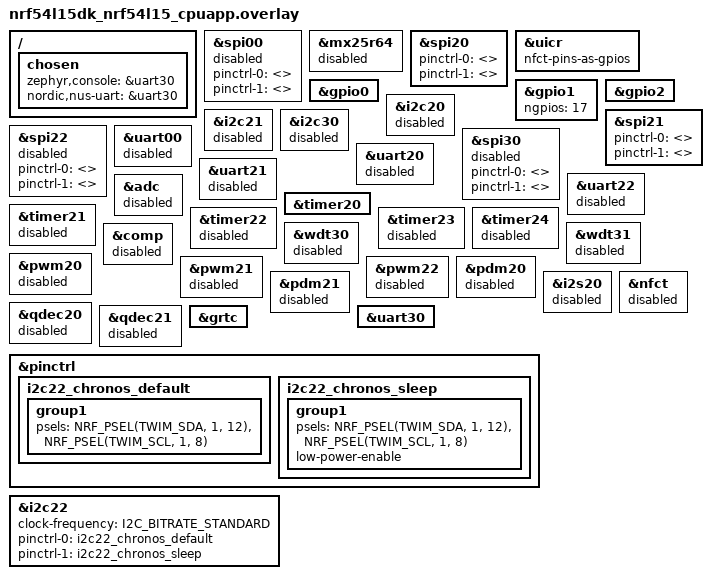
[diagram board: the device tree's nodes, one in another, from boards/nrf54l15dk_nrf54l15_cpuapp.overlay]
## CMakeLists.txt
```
cmake_minimum_required(VERSION 3.20.0)
find_package(Zephyr REQUIRED HINTS $ENV{ZEPHYR_BASE})

project(Chronos_nRF54_2)

target_sources(app PRIVATE
  src/main.c
  src/BLE.c
  src/data.c
  src/rtc_stim.c
  src/spi.c
  src/stim_nvm.c
  src/timer.c
)

if(CONFIG_BT)
  target_sources(app PRIVATE src/ble_session.c)
endif()

if(CONFIG_CHRONOS_ZMEAS)
  target_sources(app PRIVATE
    src/zmeas_gpio.c
    src/ad5933.c
  )
endif()
```

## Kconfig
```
mainmenu "Chronos"

source "Kconfig.zephyr"

config CHRONOS_ZMEAS
	bool "AD5933 impedance path (Phase A: I2C probe, P0.05 switch GPIO)"
	default y
	depends on I2C
	help
	  Enables I2C22 on P1.08 (SCL) / P1.12 (SDA), P0.05 electrode-route
	  switch GPIO, and boot-time AD5933 register readback.

config CHRONOS_ZMEAS_SWITCH_ACTIVE_HIGH
	bool "Impedance route switch: connect when P0.05 is high"
	default y
	depends on CHRONOS_ZMEAS

config CHRONOS_STIM_NVM
	bool "Persist stimulation settings in NVM (Settings/NVS + boot resume)"
	default y
	depends on BT
	help
	  Stores stim parameters and enabled flag in flash with CRC32.
	  When disabled, RAM defaults from config.h apply every boot and
	  boot-time stimulation resume is off (useful for power debugging).

	  When enabled, also set in prj.conf (Settings backend is a Kconfig
	  choice — cannot be auto-selected from here):
	    CONFIG_FLASH_MAP=y
	    CONFIG_FLASH_PAGE_LAYOUT=y
	    CONFIG_NVS=y
	    CONFIG_SETTINGS=y
	    CONFIG_SETTINGS_NVS=y
```

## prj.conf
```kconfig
##############################################################################
# BLE ON/OFF — set to n for RTC-only low-power stim (no radio)
##############################################################################
CONFIG_BT=y
CONFIG_BT_PERIPHERAL=y
CONFIG_BT_DEVICE_NAME="Chronos"
CONFIG_BT_MAX_CONN=1
CONFIG_BT_NUS=y
#CONFIG_BT_NUS_SECURITY_ENABLED=n

##############################################################################
# Peripherals: GPIO, SPIM1, TIMER0 (burst), TIMER2 (period)
##############################################################################
#CONFIG_NRFX=y
CONFIG_DEVICE_DT_METADATA=n
CONFIG_DEVICE_DEPS=n
CONFIG_NRFX_SPIM=y
CONFIG_NRFX_TIMER=y
CONFIG_GPIO=y

##############################################################################
# AD5933 / impedance (Phase A: I2C22 + P0.05 switch GPIO)
##############################################################################
CONFIG_CHRONOS_ZMEAS=y
CONFIG_CHRONOS_ZMEAS_SWITCH_ACTIVE_HIGH=y
CONFIG_I2C=y
#CONFIG_SPI=y
#CONFIG_NRFX_SPIM00=y
CONFIG_NRFX_QSPI=n
# TIMER: nRF54L15 uses TIMER20, TIMER22 etc. (enable per-instance in overlay if needed)
#CONFIG_NRFX_TIMER0=y
#CONFIG_NRFX_TIMER1=y

##############################################################################
# DK LEDs — off on custom (P1.10 = SPI MOSI; no DK LED routing)
##############################################################################
CONFIG_DK_LIBRARY=n

##############################################################################
# Heap / stacks (BLE needs more than RTC-only)
##############################################################################
CONFIG_HEAP_MEM_POOL_SIZE=8192
CONFIG_SYSTEM_WORKQUEUE_STACK_SIZE=2048
CONFIG_MAIN_STACK_SIZE=2048
CONFIG_BT_RX_STACK_SIZE=2048

##############################################################################
# UART / serial (NUS bridge on uart00; console is RTT, not UART)
# NUS sample path expects async UART; enables CONFIG_BT_NUS_UART_* sizes in Kconfig.
##############################################################################
CONFIG_SERIAL=y
CONFIG_UART_ASYNC_API=y

##############################################################################
# Console / log / debug (RTT via J-Link SWD — no UART console on custom board)
##############################################################################
CONFIG_CONSOLE=y
CONFIG_UART_CONSOLE=n
CONFIG_USE_SEGGER_RTT=y
CONFIG_RTT_CONSOLE=y
CONFIG_PRINTK=y
CONFIG_LOG=y
CONFIG_LOG_BACKEND_RTT=y
CONFIG_LOG_DEFAULT_LEVEL=2
CONFIG_DEBUG_THREAD_INFO=n
CONFIG_ASSERT=n

##############################################################################
# Boot / size
##############################################################################
CONFIG_BOOT_BANNER=n
CONFIG_NCS_BOOT_BANNER=n
CONFIG_SIZE_OPTIMIZATIONS=y

##############################################################################
# Stim NVM — set n to disable flash persistence and boot-time stim resume
# (useful for idle-current debug).
##############################################################################
CONFIG_CHRONOS_STIM_NVM=n

##############################################################################
# Flash. When CONFIG_CHRONOS_STIM_NVM=y, also uncomment the block below.
##############################################################################
CONFIG_FLASH=y
CONFIG_SPI_NOR=n
# CONFIG_FLASH_MAP=y
# CONFIG_FLASH_PAGE_LAYOUT=y
# CONFIG_NVS=y
# CONFIG_SETTINGS=y
# CONFIG_SETTINGS_NVS=y
```

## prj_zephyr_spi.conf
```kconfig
# Zephyr SPI test: use Zephyr SPI driver on spi20 instead of nrfx.
# Build with this as base conf (and zephyr_spi overlay) so CONFIG_SPI=y is set.
# Code uses #if defined(CONFIG_SPI) to run Zephyr SPI path; otherwise nrfx path.

CONFIG_SPI=y
```

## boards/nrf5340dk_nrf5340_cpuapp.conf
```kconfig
#
# Copyright (c) 2025 Nordic Semiconductor
#
# SPDX-License-Identifier: LicenseRef-Nordic-5-Clause
#

# Don't get entropy from HCI on nRF5340 devices
CONFIG_BT_HOST_CRYPTO_PRNG=y
CONFIG_ENTROPY_BT_HCI=n

# Power: use software crypto (Oberon) only; do not enable CryptoCell hardware
CONFIG_PSA_CRYPTO_DRIVER_CC3XX=n
CONFIG_PSA_CRYPTO_DRIVER_OBERON=y

# LFXO/32k RC: reverted - was increasing power on this design. Leave default (LFXO if enabled by board).
# CONFIG_CLOCK_CONTROL_NRF_K32SRC_RC=y
```

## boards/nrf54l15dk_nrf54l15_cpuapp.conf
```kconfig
#
# Copyright (c) 2024 Nordic Semiconductor
#
# SPDX-License-Identifier: LicenseRef-Nordic-5-Clause
#

# Disable the unspupported UART0 driver
CONFIG_NRFX_UARTE0=n

# nRF54L: SPIM00 (spi00) on P2.x; CS P2.05/P2.10 via direct P2 registers.
CONFIG_GPIO=y
CONFIG_NRFX_SPIM0=y
CONFIG_SPI=n

# nRF54L bring-up: 1 = main() only toggles LED1/P2.05 (no SPI/timer). Set to n for normal app.
# Alternatively set CHRONOS_NRF54L_PIN_TEST in src/config.h.
CONFIG_CHRONOS_NRF54L_PIN_TEST=n
```

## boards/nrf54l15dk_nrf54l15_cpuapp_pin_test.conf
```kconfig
# nRF54L15: Alternative way to enable pin test (Kconfig). Prefer setting CHRONOS_NRF54L_PIN_TEST=1 in src/config.h instead.
# If using this file: west build ... -- -DEXTRA_CONF_FILE=boards/nrf54l15dk_nrf54l15_cpuapp_pin_test.conf
CONFIG_CHRONOS_NRF54L_PIN_TEST=y
```

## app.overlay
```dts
/*
 * Copyright (c) 2022 Nordic Semiconductor ASA
 *
 * SPDX-License-Identifier: LicenseRef-Nordic-5-Clause
 */

/ {
	chosen {
		nordic,nus-uart = &uart00;
	};
};

/* NUS UART on P0.23 (TX), P0.25 (RX). P0.19/P0.21 are used by network core UART. */
&uart00 {
	status = "okay";
	pinctrl-0 = <&uart00_p0_23_p0_25>;
	pinctrl-1 = <&uart00_p0_23_p0_25_sleep>;
	pinctrl-names = "default", "sleep";
	current-speed = <115200>;
};

/* SPIM21: nrfx owns SPIM21 directly (spi.c). Keep node enabled for clock/power;
 * do not assign pinctrl or cs-gpios here — that fights nrfx GPIO/PSEL setup.
 */
&spi21 {
	compatible = "nordic,nrf-spim";
	status = "okay";
	pinctrl-0 = <>;
	pinctrl-1 = <>;
	pinctrl-names = "default", "sleep";
};

&pinctrl {
	uart00_p0_23_p0_25: uart00_p0_23_p0_25 {
		group1 {
			psels = <NRF_PSEL(UART_TX, 0, 23)>;
		};
		group2 {
			psels = <NRF_PSEL(UART_RX, 0, 25)>;
			bias-pull-up;
		};
	};

	uart00_p0_23_p0_25_sleep: uart00_p0_23_p0_25_sleep {
		group1 {
			psels = <NRF_PSEL(UART_TX, 0, 23)>,
				<NRF_PSEL(UART_RX, 0, 25)>;
			low-power-enable;
		};
	};
};
```

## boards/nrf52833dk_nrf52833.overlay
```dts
#include "../common-pinctrl.dtsi"

&spi1 {
    status = "okay";
    compatible = "nordic,nrf-spim";
    pinctrl-0 = <&spi_dummy>;
};
```

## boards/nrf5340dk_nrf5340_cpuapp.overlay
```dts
#include "../common-pinctrl.dtsi"

/* We're using nrfx directly, so disable Zephyr's SPI driver */
&spi1 {
    status = "disabled";
};

/* Still need to release NFC pins for GPIO use */
&gpio0 {
    status = "okay";
};

/* MBOX (IPC hardware) must be okay for BLE-over-IPC; fixes __device_dts_ord_25 undeclared. */
&mbox {
    status = "okay";
};

/*
 * Power: explicitly disable unused peripherals so they are not initialized
 * (no clocks, no power to those blocks). App uses: uart0, spi1 (nrfx), timer0/1 (nrfx), gpio, flash, mbox.
 */
&i2c0 { status = "disabled"; };
&i2c1 { status = "disabled"; };
&i2c2 { status = "disabled"; };
&i2c3 { status = "disabled"; };
&spi0 { status = "disabled"; };
&spi2 { status = "disabled"; };
&spi3 { status = "disabled"; };
&spi4 { status = "disabled"; };
&uart2 { status = "disabled"; };
&uart3 { status = "disabled"; };
&adc { status = "disabled"; };
&timer2 { status = "disabled"; };
&rtc0 { status = "disabled"; };
&rtc1 { status = "disabled"; };
&wdt1 { status = "disabled"; };
&comp { status = "disabled"; };
&pwm0 { status = "disabled"; };
&pwm1 { status = "disabled"; };
&pwm2 { status = "disabled"; };
&pwm3 { status = "disabled"; };
&pdm0 { status = "disabled"; };
&i2s0 { status = "disabled"; };
&qspi { status = "disabled"; };
&nfct { status = "disabled"; };
&qdec0 { status = "disabled"; };
&qdec1 { status = "disabled"; };
&usbd { status = "disabled"; };
&usbreg { status = "disabled"; };

/* LFXO: reverted - disabling it increased power on this design. Leave default. */
/* &lfxo { status = "disabled"; }; */

/* Power: ensure VREGH (high-voltage regulator) is off if not used. */
&vregh {
	status = "disabled";
};
```

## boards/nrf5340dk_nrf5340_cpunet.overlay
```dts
/*
 * Network core (cpunet) overlay for nRF5340 DK.
 *
 * Moves the network core UART from P1.00/P1.01 to P0.19 (TX) and P0.21 (RX)
 * so P1.00/P1.01 are free on the application core (analog switch on P1.05/P1.07/P1.13).
 * CPUNET has uart0 only (no uart1).
 *
 * Application UART0 (NUS) uses P0.23/P0.25; see app.overlay.
 */

&uart0 {
	status = "okay";
	pinctrl-0 = <&uart0_cpunet_p0_19_p0_21>;
	pinctrl-1 = <&uart0_cpunet_p0_19_p0_21_sleep>;
	pinctrl-names = "default", "sleep";
};

&pinctrl {
	uart0_cpunet_p0_19_p0_21: uart0_cpunet_p0_19_p0_21 {
		group1 {
			psels = <NRF_PSEL(UART_TX, 0, 19)>;
		};
		group2 {
			psels = <NRF_PSEL(UART_RX, 0, 21)>;
			bias-pull-up;
		};
	};

	uart0_cpunet_p0_19_p0_21_sleep: uart0_cpunet_p0_19_p0_21_sleep {
		group1 {
			psels = <NRF_PSEL(UART_TX, 0, 19)>,
				<NRF_PSEL(UART_RX, 0, 21)>;
			low-power-enable;
		};
	};
};

&gpiote1 {
	status = "okay";
};

/* Do NOT disable &gpiote here. This overlay is merged into the app build (cpuapp+cpunet);
 * the app uses GPIO0 (DAC CS, switch, etc.) which requires GPIOTE0. Disabling it caused
 * "Please enable GPIOTE instance for used GPIO port!" and NRFX_GPIOTE0_INST_IDX undeclared. */

&dppic0 {
	status = "disabled";
};

/* Do NOT disable &mbox here. This overlay is merged into the app build (cpuapp+cpunet);
 * the app needs mbox enabled for BLE-over-IPC. Disabling it caused __device_dts_ord_25
 * undeclared. The ipc_radio (network) build uses this overlay only; base cpunet DTS
 * governs mbox there. */
```

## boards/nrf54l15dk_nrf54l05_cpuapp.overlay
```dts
/*
 * Copyright (c) 2024 Nordic Semiconductor ASA
 *
 * SPDX-License-Identifier: LicenseRef-Nordic-5-Clause
 */

/ {
	chosen {
		nordic,nus-uart = &uart30;
	};
};

/* nRF54L15 DK uses UART30 for NUS; ensure it is enabled. */
&uart30 {
	status = "okay";
};
```

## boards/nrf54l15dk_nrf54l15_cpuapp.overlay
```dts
/*
 * Copyright (c) 2024 Nordic Semiconductor ASA
 *
 * SPDX-License-Identifier: LicenseRef-Nordic-5-Clause
 */
/*
 * nRF54L15 custom / QFN52: SPIM21 nrfx DAC on P1.11 SCK, P1.10 MOSI, P1.09 CS.
 * Analog switches P1.16 / P1.02 / P1.03 (timer.c). UART20 disabled on DK overlay.
 */

/* Disabled: nrfx uses SPIM21; keep mx25r64 disabled to avoid spi00 bus reference. */
&spi00 {
	status = "disabled";
	pinctrl-0 = <>;
	pinctrl-1 = <>;
	pinctrl-names = "default", "sleep";
};
&mx25r64 {
	status = "disabled";
};
/* status = "okay" so SoC domain/clock for SPIM20 is enabled; nrfx drives SPI, no Zephyr SPI driver. */
&spi20 {
	status = "okay";
	pinctrl-0 = <>;
	pinctrl-1 = <>;
	pinctrl-names = "default", "sleep";
};

/* P1.02 (NFC1) and P1.03 (NFC2) analog switches: program UICR on first boot. */
&uicr {
	nfct-pins-as-gpios;
};

&gpio0 {
	status = "okay";
};
&gpio1 {
	status = "okay";
	ngpios = <17>;
};
&gpio2 {
	status = "okay";
};
/* MBOX (IPC hardware) must be okay for BLE-over-IPC; fixes __device_dts_ord_25 undeclared. */
//&mbox {
	//status = "okay";
//};

/*
 * Power: explicitly disable unused peripherals so they are not initialized
 * (no clocks, no power to those blocks). App uses: uart30, spi20 (nrfx SPIM20), timer00/10 (nrfx), gpio, flash, mbox.
 * nRF54L15 labels: i2c20/21/22/30, spi00/20/21/22/30, uart00/20/21/22/30, timer20/21/22/23/24, etc.
 */
&i2c20 { status = "disabled"; };
&i2c21 { status = "disabled"; };
/* i2c22: AD5933 (SCL P1.08, SDA P1.12). Not i2c21 — same block as nrfx SPIM21. */
&i2c30 { status = "disabled"; };
/* spi00/spi20 cleared above for nrfx; clear pinctrl on rest to avoid device ord refs. */
&spi21 {
	status = "okay";
	pinctrl-0 = <>;
	pinctrl-1 = <>;
	pinctrl-names = "default", "sleep";
};
&spi22 {
	status = "disabled";
	pinctrl-0 = <>;
	pinctrl-1 = <>;
	pinctrl-names = "default", "sleep";
};
&spi30 {
	status = "disabled";
	pinctrl-0 = <>;
	pinctrl-1 = <>;
	pinctrl-names = "default", "sleep";
};
&uart00 { status = "disabled"; };
&uart20 { status = "disabled"; };
&uart21 { status = "disabled"; };
&uart22 { status = "disabled"; };
&adc { status = "disabled"; };
&timer20 { status = "okay"; };
&timer21 { status = "disabled"; };
&timer22 { status = "disabled"; };
&timer23 { status = "disabled"; };
&timer24 { status = "disabled"; };
&wdt30 { status = "disabled"; };
&wdt31 { status = "disabled"; };
&comp { status = "disabled"; };
&pwm20 { status = "disabled"; };
&pwm21 { status = "disabled"; };
&pwm22 { status = "disabled"; };
&pdm20 { status = "disabled"; };
&pdm21 { status = "disabled"; };
&i2s20 { status = "disabled"; };
&nfct { status = "disabled"; };
&qdec20 { status = "disabled"; };
&qdec21 { status = "disabled"; };

/* LFXO: reverted - disabling it increased power on this design. Leave default. */
/* &lfxo { status = "disabled"; }; */
/ {
	chosen {
		zephyr,console = &uart30;
		nordic,nus-uart = &uart30;
	};
};

/* nRF54L15 DK uses UART30 for NUS; ensure it is enabled. */
&uart30 {
	status = "okay";
};
&grtc {
    status = "okay";
};

&pinctrl {
	i2c22_chronos_default: i2c22_chronos_default {
		group1 {
			psels = <NRF_PSEL(TWIM_SDA, 1, 12)>,
				<NRF_PSEL(TWIM_SCL, 1, 8)>;
		};
	};

	i2c22_chronos_sleep: i2c22_chronos_sleep {
		group1 {
			psels = <NRF_PSEL(TWIM_SDA, 1, 12)>,
				<NRF_PSEL(TWIM_SCL, 1, 8)>;
			low-power-enable;
		};
	};
};

&i2c22 {
	status = "okay";
	clock-frequency = <I2C_BITRATE_STANDARD>;
	pinctrl-0 = <&i2c22_chronos_default>;
	pinctrl-1 = <&i2c22_chronos_sleep>;
	pinctrl-names = "default", "sleep";
};
```

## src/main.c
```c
/*
Author: Brandon S Coventry      Wisconsin Institute for Translational Neuroengineering
Date: 2026/02/12 Initialization
Purpose: Chronos firmware ported for the nRF54L15
Revision History: See Github history
Notes:
 - Includes the ability to turn bluetooth transmission on and off in config file. Set CONFIG_BT in config file to 0 to turn off BLE engine
 - Primary stimulation driver is still and interupt based routine. 
*/

/*Basic includes. Minimize to limit current draw from unused engines.*/
//Zephyr includes
#include <zephyr/kernel.h>
#include <zephyr/types.h>
#include <zephyr/irq.h> //Interrupt service routine handlers
#include <zephyr/device.h>  //Must import devicetree files
#include <zephyr/devicetree.h>
#include <soc.h>    //Standard System on chip imports
#include <zephyr/logging/log.h>   //Disable on compile
#include <inttypes.h>

#if defined(CONFIG_BT)
#include <zephyr/bluetooth/bluetooth.h>
#include <zephyr/bluetooth/conn.h>
#endif

//nRFX imports. Note we are primarily runnig
#include <nrfx_spim.h>
#include <nrfx_timer.h>
#include <zephyr/sys/atomic.h>
#include <hal/nrf_gpio.h>
#include <hal/nrf_clock.h>

#if defined(CONFIG_SPI)
#include <zephyr/drivers/spi.h>
#endif

//Chronos engine imports 
#include "BLE.h"  //BLE engine
#include "ble_session.h"
#include "spi.h" //SPI to howland current source
#include "timer.h"  //Handles interrupt timing of stimulation
#include "rtc_stim.h"   //handles IRQ routines for stimulation
#include "data.h"
#include "config.h"   //Set compilation settings. Look here for CONFIG_BT
#if defined(CONFIG_BT) && !defined(CONFIG_SPI)
#if defined(CONFIG_CHRONOS_STIM_NVM)
#include "stim_nvm.h"
#endif
#endif
#if defined(CONFIG_CHRONOS_ZMEAS)
#include "ad5933.h"
#endif

#define LOG_MODULE_NAME main
LOG_MODULE_REGISTER(LOG_MODULE_NAME, LOG_LEVEL_INF);

//Add UART Driver only if BLE is active. Note, UART is *virtual*, but still requires pin definitions. 
#if defined(CONFIG_BT)
#include <uart_async_adapter.h>
#include <zephyr/drivers/uart.h>
#include <zephyr/usb/usb_device.h>
#endif

//Set up peripherial initialization
static void init_clock();   //Turn on stimulation timing engine
#if defined(CONFIG_BT)
BT_CONN_CB_DEFINE(conn_callbacks) = {
	.connected        = connected,
	.disconnected     = disconnected,
	.recycled         = recycled_cb,
#ifdef CONFIG_BT_NUS_SECURITY_ENABLED
	.security_changed = security_changed,
#endif
};
#endif /* CONFIG_BT */

static void init_pins(void) {
    /* SPI CS and analog-switch GPIO (nrfx SPIM21 + timer.c). */
#if !defined(CONFIG_SPI)
    nrf_gpio_cfg_output(DAC_CS_PIN);
    nrf_gpio_pin_set(DAC_CS_PIN);   /* high (inactive) */
#endif

    nrf_gpio_cfg_output(NRF_GPIO_PIN_MAP(1, SWITCH_PIN_FIRST));
    nrf_gpio_pin_clear(NRF_GPIO_PIN_MAP(1, SWITCH_PIN_FIRST));
    nrf_gpio_cfg_output(NRF_GPIO_PIN_MAP(1, SWITCH_PIN_INTER));
    nrf_gpio_pin_clear(NRF_GPIO_PIN_MAP(1, SWITCH_PIN_INTER));
    nrf_gpio_cfg_output(NRF_GPIO_PIN_MAP(1, SWITCH_PIN_SECOND));
    nrf_gpio_pin_clear(NRF_GPIO_PIN_MAP(1, SWITCH_PIN_SECOND));
}

int main(void)
{
    //Begin with system initialization
#if defined(CONFIG_BT)
    init_clock();
#endif
    init_pins();
#if defined(CONFIG_SPI)
    /* Zephyr SPI test build: no nrfx SPI/timer activity here. */
    k_msleep(10);
#else
    /* nrfx build: initialize SPI once; transactions are driven from timer ISR. */
    spi_init();
#endif
#if defined(CONFIG_CHRONOS_ZMEAS)
    {
	    int zerr = ad5933_phase_a_probe(false);

	    if (zerr != 0) {
		    LOG_WRN("AD5933 Phase A probe failed: %d", zerr);
	    }
    }
#endif
#if defined(CONFIG_BT)
    timer_init();
#else
    timer_burst_init();
#endif
#if defined(CONFIG_BT)
    data_init_defaults();
#if !defined(CONFIG_SPI)
#if defined(CONFIG_CHRONOS_STIM_NVM)
    {
	    int nvm_err = stim_nvm_boot_load(&settings, &pending_settings);

	    (void)nvm_err;
	    update_pulse_width(settings.pulse_width);
	    update_stim_frequency(settings.frequency);
	    update_dac1_amplitude(settings.DAC_amplitude);
	    update_dac2_amplitude(settings.DAC_amplitude);
	    if (stim_nvm_wants_boot_resume()) {
		    timer_stimulation_enable_from_boot();
	    }
    }
#else
    update_pulse_width(settings.pulse_width);
    update_stim_frequency(settings.frequency);
    update_dac1_amplitude(settings.DAC_amplitude);
    update_dac2_amplitude(settings.DAC_amplitude);
#endif
#else
    update_pulse_width(settings.pulse_width);
#endif
#else
    update_pulse_width(CONFIG_PULSE_WIDTH_US);
    update_dac1_amplitude(CONFIG_STIM_AMPLITUDE);
    update_dac2_amplitude(CONFIG_STIM_AMPLITUDE);
    data_init_defaults();
#endif

#if defined(CONFIG_BT)
	/* Stimulation timer stays off until START control byte (see data.c). */
	measurement_timer_init();
	int err = 0;
	uint32_t experiment_counter = 0;

	configure_gpio();
	err = uart_init();
	if (err) {
		error();
	}

	if (IS_ENABLED(CONFIG_BT_NUS_SECURITY_ENABLED)) {
		err = bt_conn_auth_cb_register(&conn_auth_callbacks);
		if (err) {
			LOG_ERR("Failed to register authorization callbacks. (err: %d)", err);
			return 0;
		}

		err = bt_conn_auth_info_cb_register(&conn_auth_info_callbacks);
		if (err) {
			LOG_ERR("Failed to register authorization info callbacks. (err: %d)", err);
			return 0;
		}
	}

	ble_session_init();
	LOG_INF("Reed P1.15: swipe to enable BLE; stimulation off until START byte");

	/* Stimulation timer stays off until START control byte (see data.c). */
	for (;;) {
		if (MEASURE_TIMER == 1) {
			k_msleep(10000);
			experiment_counter += 10;
			error_data my_error_data;
			get_error_data(&my_error_data);
			printf("Counter: %i Elapsed: %is\nEvent0 running error: %" PRIu32
			       " avg error: %" PRIu32 " max error: %" PRIu32 "\n"
			       "Events1-3 running error: %" PRIu32 " avg error: %" PRIu32
			       " max error: %" PRIu32 ", %" PRIu32 ", %" PRIu32 "\n",
			       my_error_data.mycounter,
			       experiment_counter,
			       my_error_data.event0_error,
			       (my_error_data.event0_error / my_error_data.mycounter),
			       my_error_data.event0_max,
			       my_error_data.myerror,
			       (my_error_data.myerror / my_error_data.mycounter),
			       my_error_data.event1_max,
			       my_error_data.event2_max,
			       my_error_data.event3_max);
		} else {
			k_sleep(K_FOREVER);
		}
	}
    #else
        /* RTC low-power: no BLE; RTC wakes every stim period, timer runs one biphasic burst */
        rtc_stim_start_lfclk();
        rtc_stim_init(CONFIG_STIM_FREQUENCY_HZ);
        LOG_INF("RTC-driven stimulation at %u Hz (no BLE)", CONFIG_STIM_FREQUENCY_HZ);
        for (;;) {
            k_sleep(K_FOREVER);
        }
    #endif /* CONFIG_BT */
    }

    K_THREAD_DEFINE(ble_write_thread_id, STACKSIZE, ble_write_thread, NULL, NULL,
            NULL, PRIORITY, 0, 0);

    static void init_clock() {
#if !defined(CONFIG_SOC_NRF54L15)
        nrf_clock_hfclk_src_set(NRF_CLOCK_S, NRF_CLOCK_HFCLK_HIGH_ACCURACY);
#endif
        nrf_clock_task_trigger(NRF_CLOCK_S, NRF_CLOCK_TASK_HFCLKSTART);
        while (!nrf_clock_event_check(NRF_CLOCK_S, NRF_CLOCK_EVENT_HFCLKSTARTED)) {
            /* spin */
        }
        nrf_clock_event_clear(NRF_CLOCK_S, NRF_CLOCK_EVENT_HFCLKSTARTED);
    }
```

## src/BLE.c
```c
#if defined(CONFIG_BT)
#include <uart_async_adapter.h>
#include <zephyr/drivers/uart.h>
#include <zephyr/usb/usb_device.h>
#if IS_ENABLED(CONFIG_DK_LIBRARY)
#include <dk_buttons_and_leds.h>
#endif
#endif

#include <zephyr/types.h>
#include <zephyr/kernel.h>
#include <zephyr/device.h>
#include <zephyr/devicetree.h>
#include <soc.h>

#if defined(CONFIG_BT)
#include <zephyr/bluetooth/bluetooth.h>
#include <zephyr/bluetooth/uuid.h>
#include <zephyr/bluetooth/gatt.h>
#include <zephyr/bluetooth/hci.h>
#include <bluetooth/services/nus.h>
#include <zephyr/settings/settings.h>
#endif

#include <zephyr/sys/util.h>
#include <string.h>

#include <zephyr/logging/log.h>
#define LOG_MODULE_NAME peripheral_uart
#include "BLE.h"
#include "ble_session.h"
#include "data.h"

LOG_MODULE_REGISTER(LOG_MODULE_NAME);
K_SEM_DEFINE(ble_init_ok, 0, 1);

#if defined(CONFIG_BT)
const struct device *uart = DEVICE_DT_GET(DT_CHOSEN(nordic_nus_uart));
struct k_work_delayable uart_work;
static K_FIFO_DEFINE(fifo_uart_tx_data);
static K_FIFO_DEFINE(fifo_uart_rx_data);
#endif

#if defined(CONFIG_BT)
const struct bt_data ad[] = {
	BT_DATA_BYTES(BT_DATA_FLAGS, (BT_LE_AD_GENERAL | BT_LE_AD_NO_BREDR)),
	BT_DATA(BT_DATA_NAME_COMPLETE, DEVICE_NAME, DEVICE_NAME_LEN),
};
const size_t ad_len = ARRAY_SIZE(ad);
const struct bt_data sd[] = {
	BT_DATA_BYTES(BT_DATA_UUID128_ALL, BT_UUID_NUS_VAL),
};
const size_t sd_len = ARRAY_SIZE(sd);
struct k_work adv_work;
struct bt_conn *current_conn;
struct bt_conn *auth_conn;
bool ble_data_ready = false;
#endif

#if defined(CONFIG_BT)
void uart_work_handler(struct k_work *item)
{
	struct uart_data_t *buf;

	buf = k_malloc(sizeof(*buf));
	if (buf) {
		buf->len = 0;
	} else {
		LOG_WRN("Not able to allocate UART receive buffer");
		k_work_reschedule(&uart_work, UART_WAIT_FOR_BUF_DELAY);
		return;
	}

	uart_rx_enable(uart, buf->data, sizeof(buf->data), UART_WAIT_FOR_RX);
}

bool uart_test_async_api(const struct device *dev)
{
#if defined(CONFIG_UART_ASYNC_API)
	const struct uart_driver_api *api =
		(const struct uart_driver_api *)dev->api;

	return (api->callback_set != NULL);
#else
	ARG_UNUSED(dev);
	return false;
#endif
}
#endif

#if defined(CONFIG_BT)
void adv_work_handler(struct k_work *work)
{
	int err = bt_le_adv_start(BT_LE_ADV_CONN_FAST_2, ad, ad_len, sd, sd_len);

	if (err) {
		LOG_ERR("Advertising failed to start (err %d)", err);
		return;
	}

	LOG_INF("Advertising successfully started");
}

void advertising_start(void)
{
	k_work_submit(&adv_work);
}

void connected(struct bt_conn *conn, uint8_t err)
{
	char addr[BT_ADDR_LE_STR_LEN];

	if (err) {
		LOG_ERR("Connection failed, err 0x%02x %s", err, bt_hci_err_to_str(err));
		return;
	}

	bt_addr_le_to_str(bt_conn_get_dst(conn), addr, sizeof(addr));
	LOG_INF("Connected %s", addr);

	current_conn = bt_conn_ref(conn);

#if IS_ENABLED(CONFIG_DK_LIBRARY)
	dk_set_led_on(CON_STATUS_LED);
#endif
}

void disconnected(struct bt_conn *conn, uint8_t reason)
{
	char addr[BT_ADDR_LE_STR_LEN];

	bt_addr_le_to_str(bt_conn_get_dst(conn), addr, sizeof(addr));

	LOG_INF("Disconnected: %s, reason 0x%02x %s", addr, reason, bt_hci_err_to_str(reason));

	if (auth_conn) {
		bt_conn_unref(auth_conn);
		auth_conn = NULL;
	}

	if (current_conn) {
		bt_conn_unref(current_conn);
		current_conn = NULL;
#if IS_ENABLED(CONFIG_DK_LIBRARY)
		dk_set_led_off(CON_STATUS_LED);
#endif
	}
}

void recycled_cb(void)
{
	LOG_INF("Connection object available from previous conn. Disconnect is complete!");
	advertising_start();
}

#ifdef CONFIG_BT_NUS_SECURITY_ENABLED
void security_changed(struct bt_conn *conn, bt_security_t level,
			     enum bt_security_err err)
{
	char addr[BT_ADDR_LE_STR_LEN];

	bt_addr_le_to_str(bt_conn_get_dst(conn), addr, sizeof(addr));

	if (!err) {
		LOG_INF("Security changed: %s level %u", addr, level);
	} else {
		LOG_WRN("Security failed: %s level %u err %d %s", addr, level, err,
			bt_security_err_to_str(err));
	}
}
#endif /* CONFIG_BT_NUS_SECURITY_ENABLED */

#if defined(CONFIG_BT_NUS_SECURITY_ENABLED)
void auth_passkey_display(struct bt_conn *conn, unsigned int passkey)
{
	char addr[BT_ADDR_LE_STR_LEN];

	bt_addr_le_to_str(bt_conn_get_dst(conn), addr, sizeof(addr));

	LOG_INF("Passkey for %s: %06u", addr, passkey);
}

void auth_passkey_confirm(struct bt_conn *conn, unsigned int passkey)
{
	char addr[BT_ADDR_LE_STR_LEN];

	auth_conn = bt_conn_ref(conn);

	bt_addr_le_to_str(bt_conn_get_dst(conn), addr, sizeof(addr));

	LOG_INF("Passkey for %s: %06u", addr, passkey);

	if (IS_ENABLED(CONFIG_SOC_SERIES_NRF54HX) || IS_ENABLED(CONFIG_SOC_SERIES_NRF54LX)) {
		LOG_INF("Press Button 0 to confirm, Button 1 to reject.");
	} else {
		LOG_INF("Press Button 1 to confirm, Button 2 to reject.");
	}
}


void auth_cancel(struct bt_conn *conn)
{
	char addr[BT_ADDR_LE_STR_LEN];

	bt_addr_le_to_str(bt_conn_get_dst(conn), addr, sizeof(addr));

	LOG_INF("Pairing cancelled: %s", addr);
}


void pairing_complete(struct bt_conn *conn, bool bonded)
{
	char addr[BT_ADDR_LE_STR_LEN];

	bt_addr_le_to_str(bt_conn_get_dst(conn), addr, sizeof(addr));

	LOG_INF("Pairing completed: %s, bonded: %d", addr, bonded);
}


void pairing_failed(struct bt_conn *conn, enum bt_security_err reason)
{
	char addr[BT_ADDR_LE_STR_LEN];

	bt_addr_le_to_str(bt_conn_get_dst(conn), addr, sizeof(addr));

	LOG_INF("Pairing failed conn: %s, reason %d %s", addr, reason,
		bt_security_err_to_str(reason));
}

struct bt_conn_auth_cb conn_auth_callbacks = {
	.passkey_display = auth_passkey_display,
	.passkey_confirm = auth_passkey_confirm,
	.cancel = auth_cancel,
};

struct bt_conn_auth_info_cb conn_auth_info_callbacks = {
	.pairing_complete = pairing_complete,
	.pairing_failed = pairing_failed
};
#else
struct bt_conn_auth_cb conn_auth_callbacks;
struct bt_conn_auth_info_cb conn_auth_info_callbacks;
#endif /* CONFIG_BT_NUS_SECURITY_ENABLED */

#ifdef CONFIG_BT_NUS_SECURITY_ENABLED
void num_comp_reply(bool accept)
{
	if (accept) {
		bt_conn_auth_passkey_confirm(auth_conn);
		LOG_INF("Numeric Match, conn %p", (void *)auth_conn);
	} else {
		bt_conn_auth_cancel(auth_conn);
		LOG_INF("Numeric Reject, conn %p", (void *)auth_conn);
	}

	bt_conn_unref(auth_conn);
	auth_conn = NULL;
}

void button_changed(uint32_t button_state, uint32_t has_changed)
{
	uint32_t buttons = button_state & has_changed;

	if (auth_conn) {
		if (buttons & KEY_PASSKEY_ACCEPT) {
			num_comp_reply(true);
		}

		if (buttons & KEY_PASSKEY_REJECT) {
			num_comp_reply(false);
		}
	}
}
#endif /* CONFIG_BT_NUS_SECURITY_ENABLED */
#endif /* CONFIG_BT */

#if defined(CONFIG_BT)
void configure_gpio(void)
{
	int err;

#if IS_ENABLED(CONFIG_DK_LIBRARY)
#ifdef CONFIG_BT_NUS_SECURITY_ENABLED
	err = dk_buttons_init(button_changed);
	if (err) {
		LOG_ERR("Cannot init buttons (err: %d)", err);
	}
#endif /* CONFIG_BT_NUS_SECURITY_ENABLED */

	err = dk_leds_init();
	if (err) {
		LOG_ERR("Cannot init LEDs (err: %d)", err);
	}
#else
	ARG_UNUSED(err);
#endif
}

void error(void)
{
#if IS_ENABLED(CONFIG_DK_LIBRARY)
	dk_set_leds_state(DK_ALL_LEDS_MSK, DK_NO_LEDS_MSK);
#endif

	while (true) {
		/* Spin for ever */
		k_sleep(K_MSEC(1000));
	}
}
#endif /* CONFIG_BT */

#if defined(CONFIG_BT)
void bt_receive_cb(struct bt_conn *conn, const uint8_t *const data,
			  uint16_t len)
{
	ble_session_feed_activity();

	if (len <= BLE_DATA_BUFFER_SIZE) {
		memcpy(ble_received_data, data, len);
		ble_data_length = len;
		ble_data_ready = true;
	}

	process_received_data(&settings, ble_received_data, ble_data_length);
}

struct bt_nus_cb nus_cb = {
	.received = bt_receive_cb,
};

void ble_advertising_work_init(void)
{
	k_work_init(&adv_work, adv_work_handler);
}
#endif /* CONFIG_BT */

#if defined(CONFIG_BT)
void uart_cb(const struct device *dev, struct uart_event *evt, void *user_data)
{
	ARG_UNUSED(dev);

	static size_t aborted_len;
	struct uart_data_t *buf;
	static uint8_t *aborted_buf;
	static bool disable_req;

	switch (evt->type) {
	case UART_TX_DONE:
		LOG_DBG("UART_TX_DONE");
		if ((evt->data.tx.len == 0) ||
		    (!evt->data.tx.buf)) {
			return;
		}

		if (aborted_buf) {
			buf = CONTAINER_OF(aborted_buf, struct uart_data_t,
					   data[0]);
			aborted_buf = NULL;
			aborted_len = 0;
		} else {
			buf = CONTAINER_OF(evt->data.tx.buf, struct uart_data_t,
					   data[0]);
		}

		k_free(buf);

		buf = k_fifo_get(&fifo_uart_tx_data, K_NO_WAIT);
		if (!buf) {
			return;
		}

		if (uart_tx(uart, buf->data, buf->len, SYS_FOREVER_MS)) {
			LOG_WRN("Failed to send data over UART");
		}

		break;

	case UART_RX_RDY:
		LOG_DBG("UART_RX_RDY");
		buf = CONTAINER_OF(evt->data.rx.buf, struct uart_data_t, data[0]);
		buf->len += evt->data.rx.len;

		if (disable_req) {
			return;
		}

		if ((evt->data.rx.buf[buf->len - 1] == '\n') ||
		    (evt->data.rx.buf[buf->len - 1] == '\r')) {
			disable_req = true;
			uart_rx_disable(uart);
		}

		break;

	case UART_RX_DISABLED:
		LOG_DBG("UART_RX_DISABLED");
		disable_req = false;

		buf = k_malloc(sizeof(*buf));
		if (buf) {
			buf->len = 0;
		} else {
			LOG_WRN("Not able to allocate UART receive buffer");
			k_work_reschedule(&uart_work, UART_WAIT_FOR_BUF_DELAY);
			return;
		}

		uart_rx_enable(uart, buf->data, sizeof(buf->data),
			       UART_WAIT_FOR_RX);

		break;

	case UART_RX_BUF_REQUEST:
		LOG_DBG("UART_RX_BUF_REQUEST");
		buf = k_malloc(sizeof(*buf));
		if (buf) {
			buf->len = 0;
			uart_rx_buf_rsp(uart, buf->data, sizeof(buf->data));
		} else {
			LOG_WRN("Not able to allocate UART receive buffer");
		}

		break;

	case UART_RX_BUF_RELEASED:
		LOG_DBG("UART_RX_BUF_RELEASED");
		buf = CONTAINER_OF(evt->data.rx_buf.buf, struct uart_data_t,
				   data[0]);

		if (buf->len > 0) {
			k_fifo_put(&fifo_uart_rx_data, buf);
		} else {
			k_free(buf);
		}

		break;

	case UART_TX_ABORTED:
		LOG_DBG("UART_TX_ABORTED");
		if (!aborted_buf) {
			aborted_buf = (uint8_t *)evt->data.tx.buf;
		}

		aborted_len += evt->data.tx.len;
		buf = CONTAINER_OF((void *)aborted_buf, struct uart_data_t,
				   data[0]);

		uart_tx(uart, &buf->data[aborted_len],
			buf->len - aborted_len, SYS_FOREVER_MS);

		break;

	default:
		break;
	}
}
#endif /* CONFIG_BT */

#if defined(CONFIG_BT)
int uart_init(void)
{
	int err;
	int pos;
	struct uart_data_t *rx;
	struct uart_data_t *tx;

	if (!device_is_ready(uart)) {
		return -ENODEV;
	}

	if (IS_ENABLED(CONFIG_USB_DEVICE_STACK)) {
		err = usb_enable(NULL);
		if (err && (err != -EALREADY)) {
			LOG_ERR("Failed to enable USB");
			return err;
		}
	}

	rx = k_malloc(sizeof(*rx));
	if (rx) {
		rx->len = 0;
	} else {
		return -ENOMEM;
	}

	k_work_init_delayable(&uart_work, uart_work_handler);


	if (IS_ENABLED(CONFIG_UART_ASYNC_ADAPTER) && !uart_test_async_api(uart)) {
		/* Implement API adapter */
		uart_async_adapter_init(async_adapter, uart);
		uart = async_adapter;
	}

	err = uart_callback_set(uart, uart_cb, NULL);
	if (err) {
		k_free(rx);
		LOG_ERR("Cannot initialize UART callback");
		return err;
	}

	if (IS_ENABLED(CONFIG_UART_LINE_CTRL)) {
		LOG_INF("Wait for DTR");
		while (true) {
			uint32_t dtr = 0;

			uart_line_ctrl_get(uart, UART_LINE_CTRL_DTR, &dtr);
			if (dtr) {
				break;
			}
			/* Give CPU resources to low priority threads. */
			k_sleep(K_MSEC(100));
		}
		LOG_INF("DTR set");
		err = uart_line_ctrl_set(uart, UART_LINE_CTRL_DCD, 1);
		if (err) {
			LOG_WRN("Failed to set DCD, ret code %d", err);
		}
		err = uart_line_ctrl_set(uart, UART_LINE_CTRL_DSR, 1);
		if (err) {
			LOG_WRN("Failed to set DSR, ret code %d", err);
		}
	}

	tx = k_malloc(sizeof(*tx));

	if (tx) {
		pos = snprintf(tx->data, sizeof(tx->data),
			       "Starting Nordic UART service sample\r\n");

		if ((pos < 0) || (pos >= sizeof(tx->data))) {
			k_free(rx);
			k_free(tx);
			LOG_ERR("snprintf returned %d", pos);
			return -ENOMEM;
		}

		tx->len = pos;
	} else {
		k_free(rx);
		return -ENOMEM;
	}

	err = uart_tx(uart, tx->data, tx->len, SYS_FOREVER_MS);
	if (err) {
		k_free(rx);
		k_free(tx);
		LOG_ERR("Cannot display welcome message (err: %d)", err);
		return err;
	}

	err = uart_rx_enable(uart, rx->data, sizeof(rx->data), UART_WAIT_FOR_RX);
	if (err) {
		LOG_ERR("Cannot enable uart reception (err: %d)", err);
		/* Free the rx buffer only because the tx buffer will be handled in the callback */
		k_free(rx);
	}

	return err;
}
#endif /* CONFIG_BT */

void ble_write_thread(void)
{
#if defined(CONFIG_BT)
	/* Don't go any further until BLE is initialized */
	k_sem_take(&ble_init_ok, K_FOREVER);
	struct uart_data_t nus_data = {
		.len = 0,
	};

	for (;;) {
		/* Wait indefinitely for data to be sent over bluetooth */
		struct uart_data_t *buf = k_fifo_get(&fifo_uart_rx_data,
						     K_FOREVER);

		int plen = MIN(sizeof(nus_data.data) - nus_data.len, buf->len);
		int loc = 0;

		while (plen > 0) {
			memcpy(&nus_data.data[nus_data.len], &buf->data[loc], plen);
			nus_data.len += plen;
			loc += plen;

			if (nus_data.len >= sizeof(nus_data.data) ||
			   (nus_data.data[nus_data.len - 1] == '\n') ||
			   (nus_data.data[nus_data.len - 1] == '\r')) {
				if (bt_nus_send(NULL, nus_data.data, nus_data.len)) {
					LOG_WRN("Failed to send data over BLE connection");
				}
				nus_data.len = 0;
			}

			plen = MIN(sizeof(nus_data.data), buf->len - loc);
		}

		k_free(buf);
	}
#else
	/* BLE disabled: block thread so it never runs */
	k_sem_take(&ble_init_ok, K_FOREVER);
	for (;;) {
		k_sleep(K_FOREVER);
	}
#endif
}
```

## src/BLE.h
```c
#ifndef BLE_H
#define BLE_H

#include <zephyr/sys/util.h>
#include <zephyr/device.h>
#include <zephyr/kernel.h>

#if defined(CONFIG_BT)
#include <zephyr/bluetooth/bluetooth.h>
#include <zephyr/drivers/uart.h>
#ifdef CONFIG_UART_ASYNC_ADAPTER
#include <uart_async_adapter.h>
#endif
#endif

#if defined(CONFIG_BT)
#if defined(CONFIG_BT_NUS_THREAD_STACK_SIZE)
#define BLE_NUS_STACK_SIZE CONFIG_BT_NUS_THREAD_STACK_SIZE
#else
#define BLE_NUS_STACK_SIZE 2048
#endif
#define STACKSIZE BLE_NUS_STACK_SIZE
#define PRIORITY 7
#define DEVICE_NAME CONFIG_BT_DEVICE_NAME
#define DEVICE_NAME_LEN (sizeof(DEVICE_NAME) - 1)
#if defined(CONFIG_BT_NUS_UART_BUFFER_SIZE)
#define BLE_NUS_UART_BUF_SIZE CONFIG_BT_NUS_UART_BUFFER_SIZE
#else
#define BLE_NUS_UART_BUF_SIZE 256
#endif
#define UART_BUF_SIZE BLE_NUS_UART_BUF_SIZE
#if defined(CONFIG_BT_NUS_UART_RX_WAIT_TIME)
#define UART_WAIT_FOR_RX CONFIG_BT_NUS_UART_RX_WAIT_TIME
#else
#define UART_WAIT_FOR_RX 50000
#endif
#else
#define STACKSIZE 256
#define PRIORITY 7
#define DEVICE_NAME "Chronos"
#define DEVICE_NAME_LEN (sizeof(DEVICE_NAME) - 1)
#define UART_BUF_SIZE 40
#define UART_WAIT_FOR_RX 50000
#endif

#define RUN_LED_BLINK_INTERVAL 1000

#define UART_WAIT_FOR_BUF_DELAY K_MSEC(50)

#if defined(CONFIG_BT)
#ifdef CONFIG_UART_ASYNC_ADAPTER
UART_ASYNC_ADAPTER_INST_DEFINE(async_adapter);
#else
#define async_adapter NULL
#endif
#if IS_ENABLED(CONFIG_DK_LIBRARY)
#include <dk_buttons_and_leds.h>
#define RUN_STATUS_LED DK_LED1
#define CON_STATUS_LED DK_LED2
#define KEY_PASSKEY_ACCEPT DK_BTN1_MSK
#define KEY_PASSKEY_REJECT DK_BTN2_MSK
#else
#define RUN_STATUS_LED 0
#define CON_STATUS_LED 0
#define KEY_PASSKEY_ACCEPT 0
#define KEY_PASSKEY_REJECT 0
#endif
#else
#define RUN_STATUS_LED 0
#define CON_STATUS_LED 0
#define KEY_PASSKEY_ACCEPT 0
#define KEY_PASSKEY_REJECT 0
#endif

extern struct k_sem ble_init_ok;
#if defined(CONFIG_BT)
struct bt_nus_cb;
extern struct bt_nus_cb nus_cb;
void ble_advertising_work_init(void);
extern struct k_work_delayable uart_work;
extern const struct device *uart;
void uart_work_handler(struct k_work *item);
bool uart_test_async_api(const struct device *dev);
void configure_gpio(void);
void error(void);
void uart_cb(const struct device *dev, struct uart_event *evt, void *user_data);
int uart_init(void);
#endif
void ble_write_thread(void);

#if defined(CONFIG_BT)
extern struct k_work adv_work;
extern struct bt_conn *current_conn;
extern struct bt_conn *auth_conn;
extern const struct bt_data ad[];
extern const struct bt_data sd[];
extern const size_t ad_len;
extern const size_t sd_len;
extern bool ble_data_ready;
void adv_work_handler(struct k_work *work);
void advertising_start(void);
void connected(struct bt_conn *conn, uint8_t err);
void disconnected(struct bt_conn *conn, uint8_t reason);
void recycled_cb(void);
void bt_receive_cb(struct bt_conn *conn, const uint8_t *const data, uint16_t len);

#ifdef CONFIG_BT_NUS_SECURITY_ENABLED
void security_changed(struct bt_conn *conn, bt_security_t level,
		      enum bt_security_err err);
#endif

#if defined(CONFIG_BT_NUS_SECURITY_ENABLED)
void auth_passkey_display(struct bt_conn *conn, unsigned int passkey);
void auth_passkey_confirm(struct bt_conn *conn, unsigned int passkey);
void auth_cancel(struct bt_conn *conn);
void pairing_complete(struct bt_conn *conn, bool bonded);
void pairing_failed(struct bt_conn *conn, enum bt_security_err reason);
extern struct bt_conn_auth_cb conn_auth_callbacks;
extern struct bt_conn_auth_info_cb conn_auth_info_callbacks;
#else
extern struct bt_conn_auth_cb conn_auth_callbacks;
extern struct bt_conn_auth_info_cb conn_auth_info_callbacks;
#endif

#ifdef CONFIG_BT_NUS_SECURITY_ENABLED
void num_comp_reply(bool accept);
void button_changed(uint32_t button_state, uint32_t has_changed);
#endif
#endif /* CONFIG_BT */

struct uart_data_t {
	void *fifo_reserved;
	uint8_t data[UART_BUF_SIZE];
	uint16_t len;
};

#endif /* BLE_H */
```

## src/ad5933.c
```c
/*
 * AD5933 — Phase A: Zephyr I2C register access (no sweep yet).
 */
#if defined(CONFIG_CHRONOS_ZMEAS)

#include <errno.h>

#include <zephyr/kernel.h>
#include <zephyr/device.h>
#include <zephyr/devicetree.h>
#include <zephyr/drivers/i2c.h>
#include <zephyr/logging/log.h>

#include "ad5933.h"
#include "zmeas_gpio.h"

LOG_MODULE_REGISTER(ad5933, LOG_LEVEL_INF);

#define I2C22_NODE DT_NODELABEL(i2c22)

#if !DT_NODE_HAS_STATUS(I2C22_NODE, okay)
#error "chronos: i2c22 must be okay in board overlay (AD5933 bus)"
#endif

static const struct i2c_dt_spec ad5933_i2c = {
	.bus = DEVICE_DT_GET(I2C22_NODE),
	.addr = AD5933_I2C_ADDR_7BIT,
};

static int ad5933_read_reg(const uint8_t reg, uint8_t *buf, const size_t len)
{
	if (!device_is_ready(ad5933_i2c.bus)) {
		LOG_ERR("I2C bus not ready");
		return -ENODEV;
	}

	return i2c_write_read_dt(&ad5933_i2c, &reg, 1, buf, len);
}

int ad5933_phase_a_probe(bool connect_switch)
{
	uint8_t ctrl[2];
	uint8_t status;
	int err;

	zmeas_gpio_init();
	zmeas_gpio_switch_set(connect_switch);

	if (connect_switch) {
		k_msleep(10);
	}

	err = ad5933_read_reg(AD5933_REG_CONTROL, ctrl, sizeof(ctrl));
	if (err != 0) {
		LOG_ERR("AD5933 control read failed: %d", err);
		return err;
	}

	err = ad5933_read_reg(AD5933_REG_STATUS, &status, 1);
	if (err != 0) {
		LOG_ERR("AD5933 status read failed: %d", err);
		return err;
	}

	const uint16_t control = (uint16_t)(((uint16_t)ctrl[0] << 8) | ctrl[1]);

	LOG_INF("AD5933 Phase A OK: switch=%s control=0x%04x status=0x%02x",
		connect_switch ? "connect" : "disconnect",
		control, status);

	return 0;
}

#else /* !CONFIG_CHRONOS_ZMEAS */

#include <zephyr/kernel.h>

#include "ad5933.h"

int ad5933_phase_a_probe(bool connect_switch)
{
	ARG_UNUSED(connect_switch);
	return -ENOTSUP;
}

#endif /* CONFIG_CHRONOS_ZMEAS */
```

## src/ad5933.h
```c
#ifndef AD5933_H
#define AD5933_H

#include <stdint.h>

/** 7-bit I2C address (0x0D). */
#define AD5933_I2C_ADDR_7BIT  0x0Du

#define AD5933_REG_CONTROL  0x80u
#define AD5933_REG_STATUS    0x8Bu

/**
 * Phase A: verify I2C + read control (16-bit) and status (8-bit) registers.
 * Switch remains off unless @p connect_switch is true.
 *
 * @return 0 on successful reads, negative errno otherwise.
 */
int ad5933_phase_a_probe(bool connect_switch);

#endif /* AD5933_H */
```

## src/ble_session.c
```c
#if defined(CONFIG_BT)

#include "ble_session.h"
#include "BLE.h"

#include <zephyr/bluetooth/bluetooth.h>
#include <zephyr/bluetooth/hci.h>
#include <zephyr/bluetooth/conn.h>
#include <zephyr/device.h>
#include <zephyr/devicetree.h>
#include <zephyr/drivers/gpio.h>
#include <errno.h>
#include <zephyr/kernel.h>
#include <zephyr/logging/log.h>
#include <zephyr/sys/util.h>
#include <bluetooth/services/nus.h>
#include <zephyr/settings/settings.h>

LOG_MODULE_REGISTER(ble_session, LOG_LEVEL_INF);

/* P1.15 — pull-down; NO reed to VCC on swipe. Each rising edge toggles BLE after lockout. */
#define REED_GPIO_NODE     DT_NODELABEL(gpio1)
#define REED_PIN           15
#define REED_DEBOUNCE_MS   50
#define REED_LOCKOUT_MS    10000

static const struct device *reed_port;
static struct gpio_callback reed_gpio_cb;
static struct k_work_delayable reed_debounce_work;
static struct k_work_delayable reed_lockout_work;
static struct k_work_delayable session_inactivity_work;

static bool session_active;
static bool reed_lockout_active;
static bool ble_thread_released;
static bool nus_initialized;
static bool settings_have_loaded;

static void session_stop_internal(void);
static void inactivity_handler(struct k_work *work);
static void reed_debounce_handler(struct k_work *work);
static void reed_lockout_handler(struct k_work *work);

static void reed_irq_enable(void)
{
	if (!reed_port || !device_is_ready(reed_port)) {
		return;
	}

	(void)gpio_pin_interrupt_configure(reed_port, REED_PIN, GPIO_INT_EDGE_RISING);
}

static void reed_irq_disable(void)
{
	if (!reed_port || !device_is_ready(reed_port)) {
		return;
	}

	(void)gpio_pin_interrupt_configure(reed_port, REED_PIN, GPIO_INT_DISABLE);
}

static void reed_clear_lockout(void)
{
	k_work_cancel_delayable(&reed_lockout_work);
	reed_lockout_active = false;
	reed_irq_enable();
}

static void reed_arm_lockout(void)
{
	reed_lockout_active = true;
	reed_irq_disable();
	k_work_reschedule(&reed_lockout_work, K_MSEC(REED_LOCKOUT_MS));
}

void ble_session_feed_activity(void)
{
	if (session_active) {
		k_work_reschedule(&session_inactivity_work, K_MINUTES(5));
	}
}

static void inactivity_handler(struct k_work *work)
{
	ARG_UNUSED(work);
	if (session_active) {
		LOG_INF("BLE session: 5 min inactivity, stopping");
		session_stop_internal();
	}
}

static void session_stop_internal(void)
{
	int err;

	k_work_cancel_delayable(&reed_debounce_work);
	k_work_cancel_delayable(&session_inactivity_work);
	reed_clear_lockout();

#if IS_ENABLED(CONFIG_DK_LIBRARY)
	dk_set_led_off(RUN_STATUS_LED);
#endif

	err = bt_le_adv_stop();
	if (err && err != -EALREADY) {
		LOG_WRN("Adv stop err %d", err);
	}

	if (current_conn) {
		err = bt_conn_disconnect(current_conn, BT_HCI_ERR_REMOTE_USER_TERM_CONN);
		if (err && err != -ENOTCONN) {
			LOG_WRN("Disconnect err %d", err);
		}
	}

	err = bt_disable();
	if (err) {
		LOG_WRN("bt_disable err %d", err);
	}

	nus_initialized = false;
	session_active = false;
	LOG_INF("BLE session off");
}

static int session_start_internal(void)
{
	int err;

	if (session_active) {
		return 0;
	}

	err = bt_enable(NULL);
	if (err) {
		LOG_ERR("bt_enable failed: %d", err);
		return err;
	}

	if (IS_ENABLED(CONFIG_SETTINGS) && !settings_have_loaded) {
		settings_have_loaded = true;
		settings_load();
	}

	if (!nus_initialized) {
		err = bt_nus_init(&nus_cb);
		if (err) {
			LOG_ERR("bt_nus_init failed: %d", err);
			(void)bt_disable();
			return err;
		}
		nus_initialized = true;
	}

	if (!ble_thread_released) {
		k_sem_give(&ble_init_ok);
		ble_thread_released = true;
	}

	advertising_start();
	session_active = true;
	k_work_reschedule(&session_inactivity_work, K_MINUTES(5));
#if IS_ENABLED(CONFIG_DK_LIBRARY)
	dk_set_led_on(RUN_STATUS_LED);
#endif
	LOG_INF("BLE session on (advertising)");
	return 0;
}

static void reed_lockout_handler(struct k_work *work)
{
	ARG_UNUSED(work);

	reed_lockout_active = false;
	reed_irq_enable();
	LOG_DBG("Reed lockout expired");
}

static void reed_debounce_handler(struct k_work *work)
{
	int level;

	ARG_UNUSED(work);

	if (!reed_port || !device_is_ready(reed_port)) {
		return;
	}

	if (reed_lockout_active) {
		return;
	}

	level = gpio_pin_get(reed_port, REED_PIN);
	if (level < 0) {
		LOG_WRN("Reed pin read err %d", level);
		return;
	}

	/* NO reed: swipe pulls high; ignore spurious debounce when already released. */
	if (level == 0) {
		return;
	}

	if (!session_active) {
		LOG_INF("Reed swipe: opening BLE session");
		if (session_start_internal() == 0) {
			reed_arm_lockout();
		}
	} else {
		LOG_INF("Reed swipe: closing BLE session");
		session_stop_internal();
		reed_arm_lockout();
	}
}

static void reed_gpio_isr(const struct device *port, struct gpio_callback *cb,
			  uint32_t pins)
{
	ARG_UNUSED(port);
	ARG_UNUSED(cb);
	ARG_UNUSED(pins);

	if (reed_lockout_active) {
		return;
	}

	k_work_reschedule(&reed_debounce_work, K_MSEC(REED_DEBOUNCE_MS));
}

void ble_session_init(void)
{
	int err;

	reed_port = DEVICE_DT_GET(REED_GPIO_NODE);
	if (!device_is_ready(reed_port)) {
		LOG_ERR("GPIO1 not ready for reed (P1.15)");
		return;
	}

	err = gpio_pin_configure(reed_port, REED_PIN, GPIO_INPUT | GPIO_PULL_DOWN);
	if (err) {
		LOG_ERR("Reed pin cfg err %d", err);
		return;
	}

	err = gpio_pin_interrupt_configure(reed_port, REED_PIN, GPIO_INT_EDGE_RISING);
	if (err) {
		LOG_ERR("Reed IRQ cfg err %d", err);
		return;
	}

	gpio_init_callback(&reed_gpio_cb, reed_gpio_isr, BIT(REED_PIN));
	gpio_add_callback(reed_port, &reed_gpio_cb);

	k_work_init_delayable(&reed_debounce_work, reed_debounce_handler);
	k_work_init_delayable(&reed_lockout_work, reed_lockout_handler);
	k_work_init_delayable(&session_inactivity_work, inactivity_handler);

	reed_lockout_active = false;

	ble_advertising_work_init();

#if IS_ENABLED(CONFIG_DK_LIBRARY)
	dk_set_led_off(RUN_STATUS_LED);
#endif

	LOG_INF("Reed P1.15: each swipe toggles BLE (%d ms lockout between swipes)",
		REED_LOCKOUT_MS);
}

#endif /* CONFIG_BT */
```

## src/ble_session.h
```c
#ifndef BLE_SESSION_H
#define BLE_SESSION_H

#if defined(CONFIG_BT)

/** Reed P1.15 (NO, swipe to VCC): each rising edge toggles BLE after lockout (ble_session.c). */
void ble_session_init(void);

/** Reset 5-minute inactivity timeout (call on each NUS RX). */
void ble_session_feed_activity(void);

#else

static inline void ble_session_init(void) {}
static inline void ble_session_feed_activity(void) {}

#endif

#endif /* BLE_SESSION_H */
```

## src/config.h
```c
#ifndef CONFIG_H
#define CONFIG_H

#define MEASURE_TIMER 0 // 1: testing timer accuracy with built-in timer
                        // 0: disable measurement timer
#define SPI_VERBOSE 0   // 1: enable verbose SPI logging

/* CS hold delay: loops after nrfx_spim_xfer before cs_deselect (~2-3 us). Tune via scope:
 * Increase if CS rises before SCLK finishes; decrease if pulse is longer than needed.
 * At 64 MHz: ~32-64 = 2 us, ~64-96 = 3 us. */
#define SPI_CS_HOLD_DELAY_LOOPS  48

/* SPIM bit rate for DAC8832 (scope-tune CS hold if needed). */
#define CONFIG_SPI_FREQUENCY_HZ      2000000u

/* Biphasic square-wave stimulation (compile-time; overrides BLE) */
#define CONFIG_STIM_AMPLITUDE        0xFFAA   /* DAC amplitude (16-bit). Phase 2 = opposite. */
#define CONFIG_PULSE_WIDTH_US        200u      /* Pulse duration per phase (us). Typically 200 us. */
#define CONFIG_INTER_PHASE_GAP_US    25u       /* Gap between phase 1 and phase 2 (us); timer.h SWITCH_PERIOD. */
#define CONFIG_STIM_FREQUENCY_HZ     25u       /* Biphasic pulse rate (Hz). Test default: 25 Hz (40 ms period). */

/* DAC/op-amp settle between switch transitions and DAC updates (us). Scope-tune 5–20. */
#define CONFIG_DAC_SETTLE_US           10u

#endif // CONFIG_H
```

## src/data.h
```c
#ifndef DATA_H
#define DATA_H
#include <zephyr/types.h>

typedef struct {
	uint16_t DAC_amplitude;
	uint16_t pulse_width;
	uint16_t frequency;
} stim_setting;

/** Byte 0 of NUS payload: explicit run/stop (separate from DAC code). */
#define STIM_CTRL_STOP  0x00u
#define STIM_CTRL_START 0x01u

#define STIM_PACKET_LEN (1u + sizeof(stim_setting))

#define BLE_DATA_BUFFER_SIZE 32u

extern stim_setting settings;
extern stim_setting pending_settings;
extern uint8_t ble_received_data[];
extern uint16_t ble_data_length;

void data_init_defaults(void);
void process_received_data(stim_setting *settings, uint8_t *ble_received_data, uint16_t ble_data_length);

#endif /* DATA_H */
```
